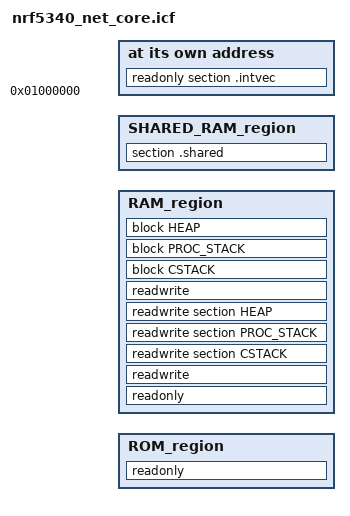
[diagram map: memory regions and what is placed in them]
/*###ICF### Section handled by ICF editor, don't touch! ****/
/*-Editor annotation file-*/
/* IcfEditorFile="$TOOLKIT_DIR$\config\linker\NordicSemi\IcfEditor\nrf53_net_v1.xml" */
/*-Specials-*/
define symbol __ICFEDIT_intvec_start__ = 0x01000000;
/*-Memory Regions-*/
define symbol __ICFEDIT_region_ROM_start__        = 0x01000000;
define symbol __ICFEDIT_region_ROM_end__          = 0x0103FFFF;
define symbol __ICFEDIT_region_RAM0_start__       = 0x21000000;
define symbol __ICFEDIT_region_RAM0_end__         = 0x21003FFF;
define symbol __ICFEDIT_region_RAM1_start__       = 0x21004000;
define symbol __ICFEDIT_region_RAM1_end__         = 0x21007FFF;
define symbol __ICFEDIT_region_RAM2_start__       = 0x21008000;
define symbol __ICFEDIT_region_RAM2_end__         = 0x2100BFFF;
define symbol __ICFEDIT_region_RAM3_start__       = 0x2100C000;
define symbol __ICFEDIT_region_RAM3_end__         = 0x2100FFFF;
define symbol __ICFEDIT_region_SHARED_RAM_start__ = 0x20070000;
define symbol __ICFEDIT_region_SHARED_RAM_end__   = 0x2007FFFF;
/*-Sizes-*/
define symbol __ICFEDIT_size_cstack__     = 0x2000;
define symbol __ICFEDIT_size_proc_stack__ = 0x0;
define symbol __ICFEDIT_size_heap__       = 0x0;
/**** End of ICF editor section. ###ICF###*/

define memory mem with size = 4G;
define symbol use_ROM  = (__ICFEDIT_region_ROM_start__  != 0x0 || __ICFEDIT_region_ROM_end__  != 0x0);
define symbol use_RAM0 = (__ICFEDIT_region_RAM0_start__ != 0x0 || __ICFEDIT_region_RAM0_end__ != 0x0);
define symbol use_RAM1 = (__ICFEDIT_region_RAM1_start__ != 0x0 || __ICFEDIT_region_RAM1_end__ != 0x0);
define symbol use_RAM2 = (__ICFEDIT_region_RAM2_start__ != 0x0 || __ICFEDIT_region_RAM2_end__ != 0x0);
define symbol use_RAM3 = (__ICFEDIT_region_RAM3_start__ != 0x0 || __ICFEDIT_region_RAM3_end__ != 0x0);
define symbol use_SHARED_RAM = (__ICFEDIT_region_SHARED_RAM_start__ != 0x0 || __ICFEDIT_region_SHARED_RAM_end__ != 0x0);

if (use_ROM)
{
  define region ROM_region = mem:[from __ICFEDIT_region_ROM_start__ to __ICFEDIT_region_ROM_end__];
}
else
{
  define region ROM_region = [];
}

if (use_RAM0)
{
  define region RAM0_region = mem:[from __ICFEDIT_region_RAM0_start__ to __ICFEDIT_region_RAM0_end__];
}
else
{
  define region RAM0_region = [];
}

if (use_RAM1)
{
  define region RAM1_region = mem:[from __ICFEDIT_region_RAM1_start__ to __ICFEDIT_region_RAM1_end__];
}
else
{
  define region RAM1_region = [];
}

if (use_RAM2)
{
  define region RAM2_region = mem:[from __ICFEDIT_region_RAM2_start__ to __ICFEDIT_region_RAM2_end__];
}
else
{
  define region RAM2_region = [];
}

if (use_RAM3)
{
  define region RAM3_region = mem:[from __ICFEDIT_region_RAM3_start__ to __ICFEDIT_region_RAM3_end__];
}
else
{
  define region RAM3_region = [];
}

define region RAM_region = RAM0_region | RAM1_region | RAM2_region | RAM3_region;

if (use_SHARED_RAM)
{
  define region SHARED_RAM_region = mem:[from __ICFEDIT_region_SHARED_RAM_start__ to __ICFEDIT_region_SHARED_RAM_end__];
}
else
{
  define region SHARED_RAM_region = [];
}

initialize by copy { readwrite };

if (isdefinedsymbol(__USE_DLIB_PERTHREAD))
{
  // Required in a multi-threaded application
  initialize by copy with packing = none { section __DLIB_PERTHREAD };
}

place at address mem:__ICFEDIT_intvec_start__ { readonly section .intvec };

if (!isempty(ROM_region))
{
  place in ROM_region  { readonly };
}
else if (!isempty(RAM_region))
{
  place in RAM_region  { readonly };
}

if (!isempty(SHARED_RAM_region))
{
  place in SHARED_RAM_region  { section .shared };
}

if (isdefinedsymbol(__STARTUP_CONFIG)) {

  /* CSTACK and HEAP sections defined in startup file. */
  keep { section CSTACK };
  keep { section PROC_STACK };
  keep { section HEAP };

  do not initialize  { section CSTACK };
  do not initialize  { section PROC_STACK };
  do not initialize  { section HEAP };

  if (!isempty(RAM_region))
  {
    place in RAM_region   { readwrite, readwrite section CSTACK, readwrite section PROC_STACK, readwrite section HEAP };
  }

} else {

  define block CSTACK     with alignment = 8, size = __ICFEDIT_size_cstack__   { };
  define block PROC_STACK with alignment = 8, size = __ICFEDIT_size_proc_stack__ { };
  define block HEAP       with alignment = 8, size = __ICFEDIT_size_heap__     { };

  if (!isempty(RAM_region))
  {
    place in RAM_region   { readwrite, block CSTACK, block PROC_STACK, block HEAP };
  }

}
